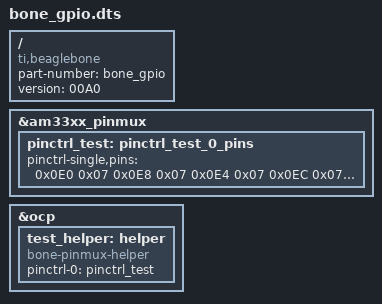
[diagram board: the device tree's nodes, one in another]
/*
* Copyright (C) 2012 Texas Instruments Incorporated - http://www.ti.com/
*
* This program is free software; you can redistribute it and/or modify
* it under the terms of the GNU General Public License version 2 as
* published by the Free Software Foundation.
*/
/dts-v1/;
/plugin/;

/ { compatible = "ti,beaglebone", "ti,beaglebone-black";

    /* identification */
    part-number = "bone_gpio";
    version     = "00A0";

    fragment@0 {
        target = <&am33xx_pinmux>;
        __overlay__ {
            pinctrl_test: pinctrl_test_0_pins {
                pinctrl-single,pins = <
                    0x0E0 0x07 /* P8_27 / GPIO2_22 / 86 OUTPUT | MODE7 */
                    0x0E8 0x07 /* P8_28 / GPIO2_24 / 88 OUTPUT | MODE7 */
                    0x0E4 0x07 /* P8_29 / GPIO2_23 / 87 OUTPUT | MODE7 */
                    0x0EC 0x07 /* P8_30 / GPIO2_25 / 89 OUTPUT | MODE7 */
                    0x0B0 0x27 /* P8_41 / GPIO2_10 / 74 INPUT  | MODE7 */
                    0x0B4 0x27 /* P8_42 / GPIO2_11 / 75 INPUT  | MODE7 */
                    0x0A8 0x27 /* P8_43 / GPIO2_8  / 72 INPUT  | MODE7 */
                    0x0AC 0x27 /* P8_44 / GPIO2_9  / 73 INPUT  | MODE7 */
                    /* Add more pins here */
                >;
            };
        };
    };

    fragment@1 {
        target = <&ocp>;
        __overlay__ {
            test_helper: helper {
                compatible = "bone-pinmux-helper";
                pinctrl-names = "default";
                pinctrl-0 = <&pinctrl_test>;
                status = "okay";
            };
        };
    };
};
